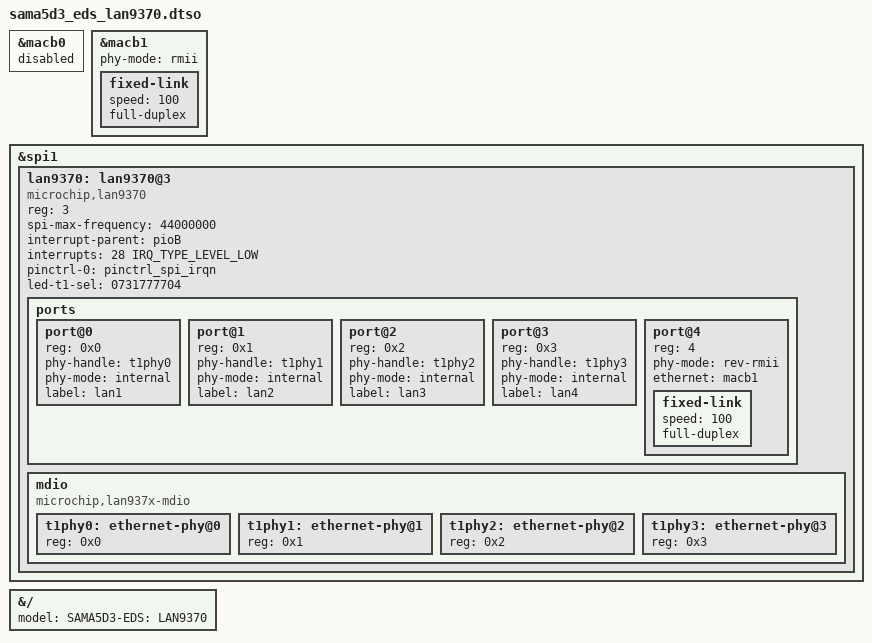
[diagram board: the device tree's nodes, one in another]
// SPDX-License-Identifier: (GPL-2.0+ OR MIT)
/*
 * Device Tree file for SAMA5D3 EDS board
 * overlay blob for the LAN9370 RMII add-on board.
 *
 * Copyright (C) 2022 Microchip Technology Inc. and its subsidiaries
 *
 * Author: Jerry Ray <jerry.ray@microchip.com>
 *
 * 5-Port 100BASE-T1 Gigabit Ethernet Switch
 * https://www.microchip.com/en-us/development-tool/EV64C55A
 *
 */
/dts-v1/;
/plugin/;

#include "dt-bindings/interrupt-controller/irq.h"
#include "dt-bindings/pinctrl/at91.h"

&macb0 {
	status = "disabled";
};

&macb1 {
	phy-mode = "rmii";
	status = "okay";

	fixed-link {
		speed = <100>;
		full-duplex;
	};
};

&spi1 {
	#address-cells = <1>;
	#size-cells = <0>;
	status = "okay";

	lan9370: lan9370@3 {
		compatible = "microchip,lan9370";
		reg = <3>;
		spi-max-frequency = <44000000>;
		interrupt-parent = <&pioB>;
		interrupts = <28 IRQ_TYPE_LEVEL_LOW>;
		pinctrl-0 = <&pinctrl_spi_irqn>;
		led-t1-sel = <0731777704>;    /* Note this value is octal. */
		status = "okay";

		ports {
			#address-cells = <1>;
			#size-cells = <0>;
			port@0 {
				reg = <0x0>;
				phy-handle = <&t1phy0>;
				phy-mode = "internal";
				label = "lan1";
			};
			port@1 {
				reg = <0x1>;
				phy-handle = <&t1phy1>;
				phy-mode = "internal";
				label = "lan2";
			};
			port@2 {
				reg = <0x2>;
				phy-handle = <&t1phy2>;
				phy-mode = "internal";
				label = "lan3";
			};
			port@3 {
				reg = <0x3>;
				phy-handle = <&t1phy3>;
				phy-mode = "internal";
				label = "lan4";
			};
			port@4 {
				reg = <4>;
				phy-mode = "rev-rmii";
				ethernet = <&macb1>;
				fixed-link {
					speed = <100>;
					full-duplex;
				};
			};
		};

		mdio {
			#address-cells = <1>;
			#size-cells = <0>;
			compatible = "microchip,lan937x-mdio";

			t1phy0: ethernet-phy@0{
				reg = <0x0>;
			};
			t1phy1: ethernet-phy@1{
				reg = <0x1>;
			};
			t1phy2: ethernet-phy@2{
				reg = <0x2>;
			};
			t1phy3: ethernet-phy@3{
				reg = <0x3>;
			};
		};
	};
};

&{/} {
	model = "SAMA5D3-EDS: LAN9370";
};
